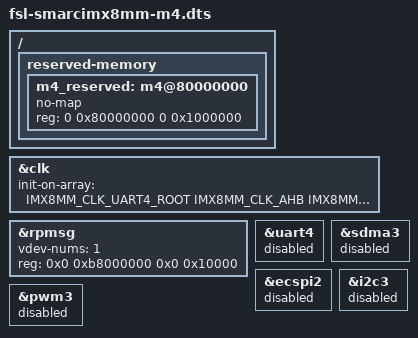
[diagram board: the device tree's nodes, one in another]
/*
 * Copyright 2018 NXP
 *
 * This program is free software; you can redistribute it and/or
 * modify it under the terms of the GNU General Public License
 * as published by the Free Software Foundation; either version 2
 * of the License, or (at your option) any later version.
 *
 * This program is distributed in the hope that it will be useful,
 * but WITHOUT ANY WARRANTY; without even the implied warranty of
 * MERCHANTABILITY or FITNESS FOR A PARTICULAR PURPOSE.  See the
 * GNU General Public License for more details.
 */

#include "fsl-smarcimx8mm.dts"

/ {
	reserved-memory {
		#address-cells = <2>;
		#size-cells = <2>;
		ranges;

		m4_reserved: m4@80000000 {
			no-map;
			reg = <0 0x80000000 0 0x1000000>;
		};

	};
};

&clk {
        init-on-array = <IMX8MM_CLK_UART4_ROOT
        IMX8MM_CLK_AHB IMX8MM_CLK_DRAM_CORE
        IMX8MM_CLK_NOC IMX8MM_CLK_NOC_APB
        IMX8MM_CLK_USB_BUS
        IMX8MM_CLK_MAIN_AXI IMX8MM_CLK_AUDIO_AHB
        IMX8MM_CLK_DRAM_APB IMX8MM_CLK_A53_DIV
        IMX8MM_ARM_PLL_OUT IMX8MM_CLK_DISP_AXI
        IMX8MM_CLK_DISP_APB
        >;
};

/*
 * ATTENTION: M4 may use IPs like below
 * ECSPI2, GPIO1/GPIO5, GPT1, I2C3, I2S0, I2S1, WDOG1, UART4, PWM3, SDMA1/3
 */

&rpmsg{
	/*
	 * 64K for one rpmsg instance:
	 * --0xb8000000~0xb800ffff: pingpong
	 */
	vdev-nums = <1>;
	reg = <0x0 0xb8000000 0x0 0x10000>;
	status = "okay";
};

&uart4 {
	status = "disabled";
};

&sdma3 {
	status = "disabled";
};

&ecspi2 {
        status = "disabled";
};

&i2c3 {
        status = "disabled";
};

&pwm3 {
        status = "disabled";
};
